# MMCSD register map
Vendor: Texas Instruments
Peripheral module from a debugger description file (folder am437x).
Registers are 32-bit, access per field, no defined reset value unless marked. A register's access mark holds for its fields unless they carry their own. Offsets are as the file gives them; lines under a group give offsets from that group; [hi:lo] are bit positions; {n}, {i} and the like mark numbered series; 'fields as' and 'values as' point back to an identical list; <NAME> marks a mode.

## MMCSD (part 1 of 2)
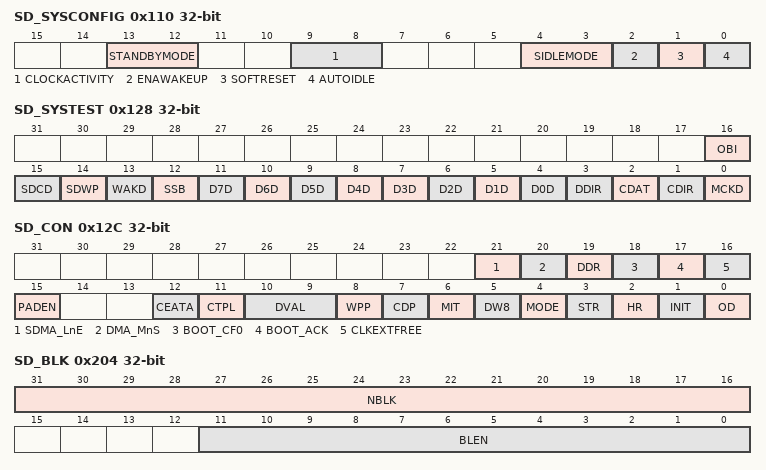
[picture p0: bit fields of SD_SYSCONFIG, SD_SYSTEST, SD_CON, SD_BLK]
0x110 SD_SYSCONFIG — This register allows controlling various parameters of the OCP interface.
  [13:12] STANDBYMODE rw — Master interface power Management, standby/wait control. [[br]]The bit field is only useful when generic parameter MADMA_EN (Master ADMA enable) is set as active, otherwise it is a read only register read a 0.
    3=en_4_0x3 (Smart-Standby wake-up-capable modelocal initiator standby status depends on local conditions, i.e. the module's functional requirement from the initiator. IP module can generate (master-related) wake-up events when in standby state. Mode is only relevant if the appropriate IP module "mwake-up" output is implemented. Functional clock is maintained. Interface clock may be switched off.); 2=en_3_0x2 (Smart-standby modelocal initiator standby status depends on local conditions, i.e. the module's functional requirement from the initiator. IP module shall not generate (initiator-related) wake-up events.); 1=en_2_0x1 (No-standby. Mstandby is never asserted.); 0=en_1_0x0 (Force-standby. Mstandby is forced unconditionally.)
  [9:8] CLOCKACTIVITY rw — Clocks activity during wake up mode period. [[br]]Bit 8 is the Interface clock. [[br]]Bit 9 is the Functional clock.
    3=en_4_0x3 (Interface and Functional clocks are maintained.); 2=en_3_0x2 (Functional clock is maintained. Interface clock may be switched-off.); 1=en_2_0x1 (Interface clock is maintained. Functional clock may be switched-off.); 0=en_1_0x0 (Interface and Functional clock may be switched off.)
  [4:3] SIDLEMODE rw — Power management
    3=en_4_0x3 (Reserved.); 2=en_3_0x2 (If an idle request is detected, the module will switch to wake up mode based on its internal activity, and the wake up capability can be used if the wake up capability is enabled (bit SD_SYSCONFIG[2] ENAWAKEUP bit is set to 1).); 1=en_2_0x1 (If an idle request is detected, the request is ignored and the module keeps on behaving normally.); 0=en_1_0x0 (If an idle request is detected, the MMC/SD/SDIO host controller acknowledges it unconditionally and goes in Inactive mode. Interrupt and DMA requests are unconditionally deasserted.)
  [2] ENAWAKEUP rw — Wake-up feature control
    1=en_2_0x1 (Wake-up capability is enabled.); 0=en_1_0x0 (Wake-up capability is disabled.)
  [1] SOFTRESET rw — Software reset. [[br]]The bit is automatically reset by the hardware. [[br]]During reset, it always returns 0.
    1=en_4_0x1 (The module is reset.); 1=en_3_0x1 (Trigger a module reset.); 0=en_2_0x0 (Normal mode); 0=en_1_0x0 (No effect)
  [0] AUTOIDLE rw — Internal Clock gating strategy
    1=en_2_0x1 (Automatic clock gating strategy is applied, based on the interconnect and MMC interface activity.); 0=en_1_0x0 (Clocks are free-running.)
0x114 SD_SYSSTATUS ro — This register provides status information about the module excluding the interrupt status information.
  [0] RESETDONE — Internal Reset Monitoring. [[br]]Note the debounce clock, the interface clock and the functional clock shall be provided to the MMC/SD/SDIO host controller to allow the internal reset monitoring.
    1=en_2_0x1 (Reset completed); 0=en_1_0x0 (Internal module reset is on-going)
0x124 SD_CSRE rw — This register enables the host controller to detect card status errors of response type R1, R1b for all cards and of R5, R5b and R6 response for cards types SD or SDIO. When a bit SD_CSRE[i] is set to 1, if the corresponding bit at the same position in the response SD_RSP10[I] is set to 1, the host controller indicates a card error (SD_STAT[28] CERR bit) interrupt status to avoid the host driver reading the response register (SD_RSP10). No automatic card error detection for autoCMD12 is implemented; the host system has to check autoCMD12 response register (SD_RSP76) for possible card errors.
  [31:0] CSRE — Card status response error
0x128 SD_SYSTEST — This register is used to control the signals that connect to I/O pins when the module is configured in system test (SYSTEST) mode for boundary connectivity verification. In SYSTEST mode, a write into SD_CMD register will not start a transfer. The buffer behaves as a stack accessible only by the local host (push and pop operations). In this mode, the Transfer Block Size (SD_BLK[10:0] BLEN bits) and the Blocks count for current transfer (SD_BLK[31:16] NBLK bits) are needed to generate a Buffer write ready interrupt (SD_STAT[4] BWR bit) or a Buffer read ready interrupt (SD_STAT[5] BRR bit) and DMA requests if enabled.
  [16] OBI rw — Out-of-band interrupt (OBI) data value.
    1=en_2_0x1 (The out-of-band interrupt pin is driven high.); 0=en_1_0x0 (The out-of-band interrupt pin is driven low.)
  [15] SDCD rw — Card detect input signal (SDCD) data value
    1=en_2_0x1 (The card detect pin is driven high.); 0=en_1_0x0 (The card detect pin is driven low.)
  [14] SDWP rw — Write protect input signal (SDWP) data value
    1=en_2_0x1 (The write protect pin SDWP is driven high.); 0=en_1_0x0 (The write protect pin SDWP is driven low.)
  [13] WAKD rw — Wake request output signal data value.
    1=en_4_0x1 (No action. Returns 1.); 1=en_3_0x1 (The pin SWAKEUP is driven high.); 0=en_2_0x0 (No action. Returns 0.); 0=en_1_0x0 (The pin SWAKEUP is driven low.)
  [12] SSB rw — Set status bit. [[br]]This bit must be cleared prior attempting to clear a status bit of the interrupt status register (SD_STAT).
    1=en_4_0x1 (No action. Returns 1.); 1=en_3_0x1 (Force to 1 all status bits of the interrupt status register (SD_STAT) only if the corresponding bit field in the Interrupt signal enable register (SD_ISE) is set.); 0=en_2_0x0 (No action. Returns 0.); 0=en_1_0x0 (Clear this SSB bit field. Writing 0 does not clear already set status bits.)
  [11] D7D rw — DAT7 input/output signal data value.
    1=en_4_0x1 (If SD_SYSTEST[3] DDIR bit = 1 (input mode direction), returns the value on the DAT7 line (high) If SD_SYSTEST[3] DDIR bit = 0 (output mode direction), returns 1.); 1=en_3_0x1 (If SD_SYSTEST[3] DDIR bit = 0 (output mode direction), the DAT7 line is driven high. If SD_SYSTEST[3] DDIR bit = 1 (input mode direction), no effect.); 0=en_2_0x0 (If SD_SYSTEST[3] DDIR bit = 0 (output mode direction), the DAT7 line is driven low. If SD_SYSTEST[3] DDIR bit = 1 (input mode direction), no effect.); 0=en_1_0x0 (If SD_SYSTEST[3] DDIR bit = 1 (input mode direction), returns the value on the DAT7 line (low). If SD_SYSTEST[3] DDIR bit = 0 (output mode direction), returns 0.)
  [10] D6D rw — DAT6 input/output signal data value.
    1=en_4_0x1 (If SD_SYSTEST[3] DDIR bit = 1 (input mode direction), returns the value on the DAT6 line (high) If SD_SYSTEST[3] DDIR bit = 0 (output mode direction), returns 1.); 1=en_3_0x1 (If SD_SYSTEST[3] DDIR bit = 0 (output mode direction), the DAT6 line is driven high. If SD_SYSTEST[3] DDIR bit = 1 (input mode direction), no effect.); 0=en_2_0x0 (If SD_SYSTEST[3] DDIR bit = 1 (input mode direction), returns the value on the DAT6 line (low). If SD_SYSTEST[3] DDIR bit = 0 (output mode direction), returns 0.); 0=en_1_0x0 (If SD_SYSTEST[3] DDIR bit = 0 (output mode direction), the DAT6 line is driven low. If SD_SYSTEST[3] DDIR bit = 1 (input mode direction), no effect.)
  [9] D5D rw — DAT5 input/output signal data value.
    1=en_4_0x1 (If SD_SYSTEST[3] DDIR bit = 1 (input mode direction), returns the value on the DAT5 line (high) If SD_SYSTEST[3] DDIR bit = 0 (output mode direction), returns 1.); 1=en_3_0x1 (If SD_SYSTEST[3] DDIR bit = 0 (output mode direction), the DAT5 line is driven high. If SD_SYSTEST[3] DDIR bit = 1 (input mode direction), no effect.); 0=en_2_0x0 (If SD_SYSTEST[3] DDIR bit = 0 (output mode direction), the DAT5 line is driven low. If SD_SYSTEST[3] DDIR bit = 1 (input mode direction), no effect.); 0=en_1_0x0 (If SD_SYSTEST[3] DDIR bit = 1 (input mode direction), returns the value on the DAT5 line (low). If SD_SYSTEST[3] DDIR bit = 0 (output mode direction), returns 0.)
  [8] D4D rw — DAT4 input/output signal data value.
    1=en_4_0x1 (If SD_SYSTEST[3] DDIR bit = 1 (input mode direction), returns the value on the DAT4 line (high) If SD_SYSTEST[3] DDIR bit = 0 (output mode direction), returns 1.); 1=en_3_0x1 (If SD_SYSTEST[3] DDIR bit = 0 (output mode direction), the DAT4 line is driven high. If SD_SYSTEST[3] DDIR bit = 1 (input mode direction), no effect.); 0=en_2_0x0 (If SD_SYSTEST[3] DDIR bit = 1 (input mode direction), returns the value on the DAT4 line (low). If SD_SYSTEST[3] DDIR bit = 0 (output mode direction), returns 0.); 0=en_1_0x0 (If SD_SYSTEST[3] DDIR bit = 0 (output mode direction), the DAT4 line is driven low. If SD_SYSTEST[3] DDIR bit = 1 (input mode direction), no effect.)
  [n+4] D{n}D rw (n=0..3) — DAT{n} input/output signal data value.
    1=en_4_0x1 (If SD_SYSTEST[3] DDIR bit = 0 (output mode direction), the DAT{n} line is driven high. If SD_SYSTEST[3] DDIR bit = 1 (input mode direction), no effect.); 1=en_3_0x1 (If SD_SYSTEST[3] DDIR bit = 1 (input mode direction), returns the value on the DAT{n} line (high) If SD_SYSTEST[3] DDIR bit = 0 (output mode direction), returns 1.); 0=en_2_0x0 (If SD_SYSTEST[3] DDIR bit = 1 (input mode direction), returns the value on the DAT{n} line (low). If SD_SYSTEST[3] DDIR bit = 0 (output mode direction), returns 0.); 0=en_1_0x0 (If SD_SYSTEST[3] DDIR bit = 0 (output mode direction), the DAT{n} line is driven low. If SD_SYSTEST[3] DDIR bit = 1 (input mode direction), no effect.)
  [3] DDIR rw — Control of the DAT[[br]][7:0] pins direction.
    1=en_4_0x1 (No action. Returns 1.); 1=en_3_0x1 (The DAT lines are inputs (card to host).); 0=en_2_0x0 (No action. Returns 0.); 0=en_1_0x0 (The DAT lines are outputs (host to card).)
  [2] CDAT rw — CMD input/output signal data value
    1=en_4_0x1 (If SD_SYSTEST[1] CDIR bit = 0 (output mode direction), the CMD line is driven high. If SD_SYSTEST[1] CDIR bit = 1 (input mode direction), no effect.); 1=en_3_0x1 (If SD_SYSTEST[1] CDIR bit = 1 (input mode direction), returns the value on the CMD line (high) If SD_SYSTEST[1] CDIR bit = 0 (output mode direction), returns 1 .); 0=en_2_0x0 (If SD_SYSTEST[1] CDIR bit = 0 (output mode direction), the CMD line is driven low. If SD_SYSTEST[1] CDIR bit = 1 (input mode direction), no effect.); 0=en_1_0x0 (If SD_SYSTEST[1] CDIR bit = 1 (input mode direction), returns the value on the CMD line (low). If SD_SYSTEST[1] CDIR bit = 0 (output mode direction), returns 0 .)
  [1] CDIR rw — Control of the CMD pin direction
    1=en_4_0x1 (The CMD line is an input (card to host) .); 1=en_3_0x1 (No action. Returns 1.); 0=en_2_0x0 (No action. Returns 0.); 0=en_1_0x0 (The CMD line is an output (host to card).)
  [0] MCKD rw — MMC clock output signal data value
    1=en_4_0x1 (No action. Returns 1.); 1=en_3_0x1 (The output clock is driven high.); 0=en_2_0x0 (No action. Returns 0.); 0=en_1_0x0 (The output clock is driven low.)
0x12C SD_CON — This register is used: To select the functional mode for any card. To send an initialization sequence to any card. To send an initialization sequence to any card. To enable the detection on the mmc_dat[1] signal of a card interrupt for SDIO cards only. It also configures the parameters related to the card detect and write protect input signals
  [21] SDMA_LnE rw — Slave DMA Level/Edge Request. [[br]]The waveform of the DMA request can be configured either edge sensitive with early de-assertion on first access to SD_DATA register or late de-assertion, request remains active until last allowed data written into SD_DATA. [[br]]
    1=en_2_0x1 (Slave DMA level sensitive.); 0=en_1_0x0 (Slave DMA edge sensitive.)
  [20] DMA_MnS rw — DMA Master or Slave selection. [[br]]When this bit is set and the controller is configured to use the DMA, Ocp master interface is used to get datas from system using ADMA2 procedure (direct access to the memory). [[br]]This option is only available if generic parameter MADMA_EN is asserted to 1. [[br]]
    1=en_2_0x1 (Not available on this device.); 0=en_1_0x0 (The controller is slave on data transfers with system.)
  [19] DDR rw — Dual Data Rate mode. [[br]]When this register is set, the controller uses both clock edge to emit or receive data. [[br]]Odd bytes are transmitted on falling edges and even bytes are transmitted on rise edges. [[br]]It only applies on Data bytes and CRC, Start, end bits and CRC status are kept full cycle. [[br]]This bit field is only meaningful and active for even clock divider ratio of SD_SYSCTL[CLKD], it is insensitive to SD_HCTL[HSPE] setting. [[br]]Note: DDR mode is not supported on this device. [[br]]Always set this bit to 0.
    1=en_2_0x1 (Data Bytes and CRC are transmitted on both edges.); 0=en_1_0x0 (Standard modeData are transmitted on a single edge.)
  [18] BOOT_CF0 rw — Boot Status Supported. [[br]]This register is set when the CMD line needs to be forced to 0 for a boot sequence. [[br]]CMD line is driven to 0 after writing in SD_CMD. [[br]]The line is released when this bit field is de-asserted and aborts data transfer in case of a pending transaction. [[br]]
    1=en_4_0x1 (CMD line forced to 0 is enabled and will be active after writing into SD_CMD register.); 1=en_3_0x1 (CMD line is released when it was previously forced to 0 by a boot sequence.); 0=en_2_0x0 (CMD line forced to 0 is enabled.); 0=en_1_0x0 (CMD line not forced.)
  [17] BOOT_ACK rw — Book acknowledge received. [[br]]When this bit is set the controller should receive a boot status on DAT0 line after next command issued. [[br]]If no status is received a data timeout will be generated.
    1=en_2_0x1 (A boot status will be received on DAT0 line after issuing a command.); 0=en_1_0x0 (No acknowledge to be received.)
  [16] CLKEXTFREE rw — External clock free running. [[br]]This register is used to maintain card clock out of transfer transaction to enable slave module (for example to generate a synchronous interrupt on mmc_dat[1] ). [[br]]The Clock will be maintain only if SD_SYSCTL[2] CEN bit is set.
    1=en_2_0x1 (External card clock is maintain even out of active transaction period only if SD_SYSCTL[2] CEN bit is set.); 0=en_1_0x0 (External card clock is cut off outside active transaction period.)
  [15] PADEN rw — Control power for MMC lines. [[br]]This register is only useful when MMC PADs contain power saving mechanism to minimize its leakage power. [[br]]It works as a GPIO that directly control the ACTIVE pin of PADs. [[br]]Excepted for mmc_dat[1] , the signal is also combine outside the module with the dedicated power control SD_CON[11] CTPL bit.
    1=en_2_0x1 (ADPIDLE module pin is forced to active state); 0=en_1_0x0 (ADPIDLE module pin is not forced, it is automatically generated by the MMC fsms.)
  [12] CEATA rw — CE-ATA control mode (MMC cards compliant with CE-ATA). [[br]]This bit selects the active level of the out-of-band interrupt coming from MMC cards. [[br]]The usage of the Out-of-Band signal (OBI) is not supported.
    1=en_2_0x1 (CE-ATA mode. Next commands are considered as CE-ATA commands.); 0=en_1_0x0 (Standard MMC/SD/SDIO mode.)
  [11] CTPL rw — Control Power for mmc_dat[1] line (SD cards). [[br]]By default, this bit is cleared to 0 and the host controller automatically disables all the input buffers outside of a transaction to minimize the leakage current. [[br]]SDIO cards. [[br]]When this bit is set to 1, the host controller automatically disables all the input buffers except the buffer of mmc_dat[1] outside of a transaction in order to detect asynchronous card interrupt on mmc_dat[1] line and minimize the leakage current of the buffers.
    1=en_2_0x1 (Disable all the input buffers except the buffer of mmc_dat[1] outside of a transaction.); 0=en_1_0x0 (Disable all the input buffers outside of a transaction.)
  [10:9] DVAL rw — Debounce filter value (all cards). [[br]]This register is used to define a debounce period to filter the card detect input signal (SDCD). [[br]]The usage of the card detect input signal (SDCD) is optional and depends on the system integration and the type of the connector housing that accommodates the card.
    3=en_4_0x3 (8.4 ms debounce period); 2=en_3_0x2 (1 ms debounce period); 1=en_2_0x1 (231 us debounce period); 0=en_1_0x0 (33 us debounce period)
  [8] WPP rw — Write protect polarity (SD and SDIO cards only). [[br]]This bit selects the active level of the write protect input signal (SDWP). [[br]]The usage of the write protect input signal (SDWP) is optional and depends on the system integration and the type of the connector housing that accommodates the card.
    1=en_2_0x1 (Active low level); 0=en_1_0x0 (Active high level)
  [7] CDP rw — Card detect polarity (all cards). [[br]]This bit selects the active level of the write protect input signal (SDWP). [[br]]The usage of the write protect input signal (SDWP) is optional and depends on the system integration and the type of the connector housing that accommodates the card.
    values as WPP
  [6] MIT rw — MMC interrupt command (MMC cards only). [[br]]This bit must be set to 1, when the next write access to the command register (SD_CMD) is for writing a MMC interrupt command (CMD40) requiring the command timeout detection to be disabled for the command response.
    1=en_2_0x1 (Command timeout disabled.); 0=en_1_0x0 (Command timeout enabled.)
  [5] DW8 rw — [[br]]8-bit mode MMC select (MMC cards only). [[br]]For SD/SDIO cards, this bit must be cleared to 0. [[br]]For MMC card, this bit must be set following a valid SWITCH command (CMD6) with the correct value and extend CSD index written in the argument. [[br]]Prior to this command, the MMC card configuration register (CSD and EXT_CSD) must be verified for compliancy with MMC standard specification.
    1=en_2_0x1 (8-bit data width); 0=en_1_0x0 (1-bit or 4-bit data width)
  [4] MODE rw — Mode select (all cards). [[br]]This bit selects the functional mode.
    1=en_2_0x1 (SYSTEST mode. SYSTEST mode. The signal pins are configured as general-purpose input/output and the 1024-byte buffer is configured as a stack memory accessible only by the local host or system DMA. The pins retain their default type (input, output or in-out). SYSTEST mode is operated under the control of the SYSTEST register.); 0=en_1_0x0 (Functional mode. Transfers to the MMC/SD/SDIO cards follow the card protocol. The MMC clock is enabled. MMC/SD transfers are operated under the control of the SD_CMD register.)
  [3] STR rw — Stream command (MMC cards only). [[br]]This bit must be set to 1 only for the stream data transfers (read or write) of the adtc commands. [[br]]Stream read is a class 1 command (CMD11READ_DAT_UNTIL_STOP). [[br]]Stream write is a class 3 command (CMD20WRITE_DAT_UNTIL_STOP).
    1=en_2_0x1 (Stream oriented data transfer); 0=en_1_0x0 (Block oriented data transfer)
  [2] HR rw — Broadcast host response (MMC cards only). [[br]]This register is used to force the host to generate a [[br]]48-bit response for bc command type. [[br]]It can be used to terminate the interrupt mode by generating a CMD40 response by the core. [[br]]In order to have the host response to be generated in open drain mode, the register SD_CON[OD] must be set to 1. [[br]]When SD_CON[12] CEATA bit is set to 1 and SD_ARG cleared to 0, when writing 0000 0000h into SD_CMD register, the host controller performs a 'command completion signal disable' token (i.e., mmc_cmd line held to 0 during 47 cycles followed by a 1).
    1=en_2_0x1 (The host generates a 48-bit response instead of a command or a command completion signal disable token.); 0=en_1_0x0 (The host does not generate a 48-bit response instead of a command.)
  [1] INIT rw — Send initialization stream (all cards). [[br]]When this bit is set to 1, and the card is idle, an initialization sequence is sent to the card. [[br]]An initialization sequence consists of setting the mmc_cmd line to 1 during 80 clock cycles. [[br]]The initialization sequence is mandatory - but it is not required to do it through this bit - this bit makes it easier. [[br]]Clock divider (SD_SYSCTL[[br]][15:6] CLKD bits) should be set to ensure that 80 clock periods are greater than 1ms. [[br]]Note: In this mode, there is no command sent to the card and no response is expected. [[br]]A command complete interrupt will be generated once the initialization sequence is completed. [[br]]SD_STAT[0] CC bit can be polled.
    1=en_2_0x1 (The host sends an initialization sequence); 0=en_1_0x0 (The host does not send an initialization sequence)
  [0] OD rw — Card open drain mode (MMC cards only). [[br]]This bit must be set to 1 for MMC card commands 1, 2, 3 and 40, and if the MMC card bus is operating in open-drain mode during the response phase to the command sent. [[br]]Typically, during card identification mode when the card is either in idle, ready or ident state. [[br]]It is also necessary to set this bit to 1, for a broadcast host response (see Broadcast host response register SD_CON[2] HR bit).
    1=en_2_0x1 (Open drain or broadcast host response); 0=en_1_0x0 (No open drain)
0x130 SD_PWCNT — This register is used to program a mmc counter to delay command transfers after activating the PAD power, this value depends on PAD characteristics and voltage.
  [15:0] PWRCNT rw — Power counter register. [[br]]This register is used to introduce a delay between the PAD ACTIVE pin assertion and the command issued.
    0xFFFF=en_5_0xFFFF (TCF x 65535 delay (card clock period)); 0xFFFE=en_4_0xFFFE (TCF x 65534 delay (card clock period)); 2=en_3_0x2 (TCF x 2 delay (card clock period)); 1=en_2_0x1 (TCF delay (card clock period)); 0=en_1_0x0 (No additional delay added)
0x200 SD_SDMASA ro — This register is used to program a mmc counter to delay command transfers after activating the PAD power. This value depends on PAD characteristics and voltage.
  [31:0] SDMA_SYSADDR — This register contains the system memory address for a SDMA transfer. [[br]]When the Host Controller stops a SDMA transfer, this register shall point to the system address of the next contiguous data position. [[br]]It can be accessed only if no transaction is executing (i.e., after a transaction has stopped). [[br]]Read operations during transfers may return an invalid value. [[br]]The Host Driver shall initialize this register before starting a SDMA transaction. [[br]]After SDMA has stopped, the next system address of the next contiguous data position can be read from this register. [[br]]The SDMA transfer waits at the every boundary specified by the Host SDMA Buffer Boundary in the Block Size register. [[br]]The Host Controller generates DMA Interrupt to request the Host Driver to update this register. [[br]]The Host Driver sets the next system address of the next data position to this register. [[br]]When the most upper byte of this register (003h) is written, the Host Controller restarts the SDMA transfer. [[br]]When restarting SDMA by the Resume command or by setting Continue Request in the Block Gap Control register, the Host Controller shall start at the next contiguous address stored here in the SDMA System Address register. [[br]]ADMA does not use this register.
0x204 SD_BLK — This register shall be used for any card. SD_BLK[BLEN] is the block size register. SD_BLK[NBLK] is the block count register.
  [31:16] NBLK rw — Blocks count for current transfer. [[br]]This register is enabled when Block count Enable (SD_CMD[1] BCE bit) is set to 1 and is valid only for multiple block transfers. [[br]]Setting the block count to 0 results no data blocks being transferred. [[br]]Note: The host controller decrements the block count after each block transfer and stops when the count reaches zero. [[br]]This register can be accessed only if no transaction is executing (i.e., after a transaction has stopped). [[br]]Read operations during transfers may return an invalid value and write operation will be ignored. [[br]]In suspend context, the number of blocks yet to be transferred can be determined by reading this register. [[br]]When restoring transfer context prior to issuing a Resume command, The local host shall restore the previously saved block count.
    0xFFFF=en_4_0xFFFF (65535 blocks); 2=en_3_0x2 (2 blocks); 1=en_2_0x1 (1 block); 0=en_1_0x0 (Stop count)
  [11:0] BLEN rw — Transfer block size. [[br]]This register specifies the block size for block data transfers. [[br]]Read operations during transfers may return an invalid value, and write operations are ignored. [[br]]When a CMD12 command is issued to stop the transfer, a read of the BLEN field after transfer completion (SD_STAT[1] TC bit set to 1) will not return the true byte number of data length while the stop occurs but the value written in this register before transfer is launched.
    0x800=en_8_0x800 (2048 bytes block length); 0x7FF=en_7_0x7FF (2047 bytes block length); 0x200=en_6_0x200 (512 bytes block length); 0x1FF=en_5_0x1FF (511 bytes block length); 3=en_4_0x3 (3 bytes block length); 2=en_3_0x2 (2 bytes block length); 1=en_2_0x1 (1 byte block length); 0=en_1_0x0 (No data transfer)
0x208 SD_ARG rw — This register contains command argument specified as bit 39-8 of Command-Format. These registers must be initialized prior to sending the command itself to the card (write action into the register SD_CMD register). Only exception is for a command index specifying stuff bits in arguments, making a write unnecessary.
  [31:0] ARG — Command argument bits [31:0] .
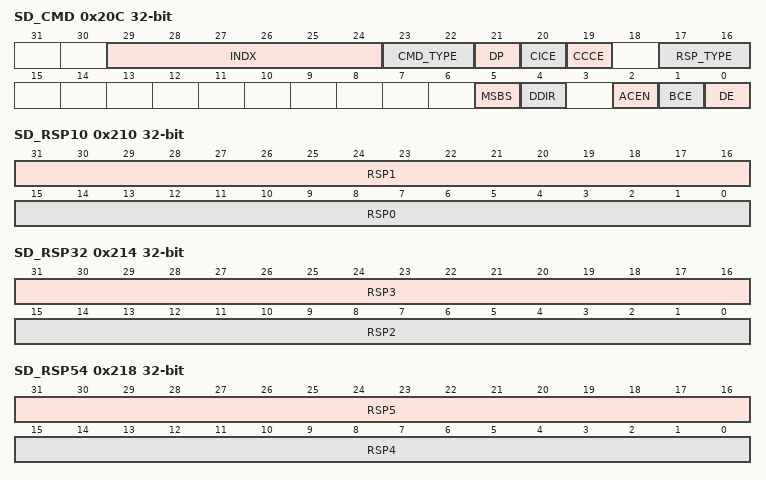
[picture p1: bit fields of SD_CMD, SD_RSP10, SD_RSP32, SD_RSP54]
0x20C SD_CMD — SD_CMD[31:16] = the command register. SD_CMD[15:0] = the transfer mode. This register configures the data and command transfers. A write into the most significant byte send the command. A write into SD_CMD[15:0] registers during data transfer has no effect. This register can be used for any card. In SYSTEST mode, a write into SD_CMD register will not start a transfer.
  [29:24] INDX rw — Command index binary encoded value from 0 to 63 specifying the command number send to card (CMD0 or ACMD0 to CMD63 or ACMD63).
  [23:22] CMD_TYPE rw — Command type. [[br]]This register specifies three types of special commands: Suspend, Resume and Abort. [[br]]These bits shall be cleared to 0b00 for all other commands.
    3=en_4_0x3 (Upon CMD12 or CMD52 "I/O Abort" command); 2=en_3_0x2 (Upon CMD52 "Function Select" operation); 1=en_2_0x1 (Upon CMD52 "Bus Suspend" operation); 0=en_1_0x0 (Others commands)
  [21] DP rw — Data present select. [[br]]This register indicates that data is present and mmc_dat line shall be used. [[br]]It must be cleared to 0 in the following conditions: Command using only mmc_cmd line. [[br]]Command with no data transfer but using busy signal on mmc_dat0. [[br]]Resume command.
    1=en_2_0x1 (Command with data transfer); 0=en_1_0x0 (Command with no data transfer)
  [20] CICE rw — Command Index check enable. [[br]]This bit must be set to 1 to enable index check on command response to compare the index field in the response against the index of the command. [[br]]If the index is not the same in the response as in the command, it is reported as a command index error (SD_STAT[19] CIE bit set to1) Note: The CICE bit cannot be configured for an Auto CMD12, then index check is automatically checked when this command is issued.
    1=en_2_0x1 (Index check enable); 0=en_1_0x0 (Index check disable)
  [19] CCCE rw — Command CRC check enable. [[br]]This bit must be set to 1 to enable CRC7 check on command response to protect the response against transmission errors on the bus. [[br]]If an error is detected, it is reported as a command CRC error (SD_STAT[17] CCRC bit set to 1). [[br]]Note: The CCCE bit cannot be configured for an Auto CMD12, and then CRC check is automatically checked when this command is issued.
    1=en_2_0x1 (CRC7 check enable); 0=en_1_0x0 (CRC7 check disable)
  [17:16] RSP_TYPE rw — Response type. [[br]]This bits defines the response type of the command.
    3=en_4_0x3 (Response Length 48 bits with busy after response); 2=en_3_0x2 (Response Length 48 bits); 1=en_2_0x1 (Response Length 136 bits); 0=en_1_0x0 (No response)
  [5] MSBS rw — Multi/Single block select. [[br]]This bit must be set to 1 for data transfer in case of multi block command. [[br]]For any others command this bit shall be cleared to 0.
    1=en_2_0x1 (Multi block. When Block Count is disabled (SD_CMD[1] BCE bit is cleared to 0) in Multiple block transfers (SD_CMD[5] MSBS bit is set to 1), the module can perform infinite transfer.); 0=en_1_0x0 (Single block. If this bit is 0, it is not necessary to set the register SD_BLK[31:16] NBLK bits.)
  [4] DDIR rw — Data transfer Direction. [[br]]Select This bit defines either data transfer will be a read or a write.
    1=en_2_0x1 (Data Read (card to host)); 0=en_1_0x0 (Data Write (host to card))
  [2] ACEN rw — Auto CMD12 Enable (SD cards only). [[br]]When this bit is set to 1, the host controller issues a CMD12 automatically after the transfer completion of the last block. [[br]]The Host Driver shall not set this bit to issue commands that do not require CMD12 to stop data transfer. [[br]]In particular, secure commands do not require CMD12. [[br]]For CE-ATA commands (SD_CON[12] CEATA bit set to 1), auto CMD12 is useless[[br]] therefore when this bit is set the mechanism to detect command completion signal, named CCS, interrupt is activated.
    1=en_2_0x1 (Auto CMD12 enable or CCS detection enabled.); 0=en_1_0x0 (Auto CMD12 disable)
  [1] BCE rw — Block Count Enable (Multiple block transfers only). [[br]]This bit is used to enable the block count register (SD_BLK[[br]][31:16] NBLK bits). [[br]]When Block Count is disabled (SD_CMD[1] BCE bit is cleared to 0) in Multiple block transfers (SD_CMD[5] MSBS bits is set to 1), the module can perform infinite transfer.
    1=en_2_0x1 (Block count enabled for multiple block transfer with known number of blocks); 0=en_1_0x0 (Block count disabled for infinite transfer.)
  [0] DE rw — DMA Enable. [[br]]This bit is used to enable DMA mode for host data access.
    1=en_2_0x1 (DMA mode enable); 0=en_1_0x0 (DMA mode disable)
0x210 SD_RSP10 ro — This 32-bit register holds bits positions [31:0] of command response type R1, R1b, R2, R3, R4, R5, R5b, or R6.
  [31:16] RSP1 — Command Response [[br]][31:16]
  [15:0] RSP0 — Command Response [[br]][15:0]
0x214 SD_RSP32 ro — This 32-bit register holds bits positions [63:32] of command response type R2.
  [31:16] RSP3 — Command Response [[br]][63:48]
  [15:0] RSP2 — Command Response [[br]][47:32]
0x218 SD_RSP54 ro — This 32-bit register holds bits positions [95:64] of command response type R2.
  [31:16] RSP5 — Command Response [[br]][95:80]
  [15:0] RSP4 — Command Response [[br]][79:64]
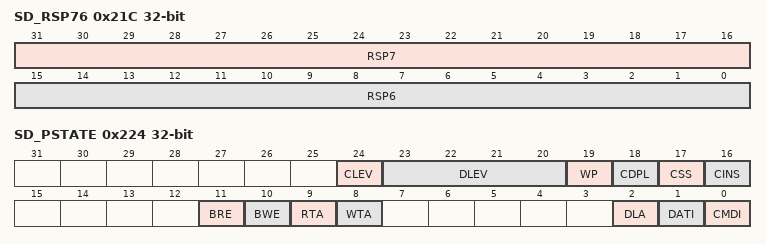
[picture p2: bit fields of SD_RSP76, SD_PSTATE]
0x21C SD_RSP76 ro — This 32-bit register holds bits positions [127:96] of command response type R2.
  [31:16] RSP7 — Command Response [[br]][127:112]
  [15:0] RSP6 — Command Response [[br]][111:96]
0x220 SD_DATA rw — This register is the 32-bit entry point of the buffer for read or write data transfers. The buffer size is 32bitsx256(1024 bytes). Bytes within a word are stored and read in little endian format. This buffer can be used as two 512 byte buffers to transfer data efficiently without reducing the throughput. Sequential and contiguous access is necessary to increment the pointer correctly. Random or skipped access is not allowed. In little endian, if the local host accesses this register byte-wise or 16bit-wise, the least significant byte (bits [7:0]) must always be written/read first. The update of the buffer address is done on the most significant byte write for full 32-bit DATA register or on the most significant byte of the last word of block transfer. Example 1Byte or 16-bit access: Mbyteen[3:0]=0001 (1-byte) => Mbyteen[3:0]=0010 (1-byte) => Mbyteen[3:0]=1100 (2-bytes) OK. Mbyteen[3:0]=0001 (1-byte) => Mbyteen[3:0]=0010 (1-byte) => Mbyteen[3:0]=0100 (1-byte) OK. Mbyteen[3:0]=0001 (1-byte) => Mbyteen[3:0]=0010 (1-byte) => Mbyteen[3:0]=1000 (1-byte) Bad.
  [31:0] DATA — Data register [31:0]. [[br]]In functional mode (SD_CON[4] MODE bit set to the default value 0): A read access to this register is allowed only when the buffer read enable status is set to 1 (SD_PSTATE[11] BRE bit), otherwise a bad access (SD_STAT[29] BADA bit) is signaled. [[br]]A write access to this register is allowed only when the buffer write enable status is set to 1 (SD_PSTATE[10] BWE bit), otherwise a bad access (SD_STAT[29] BADA bit) is signaled and the data is not written.
0x224 SD_PSTATE ro — The Host can get the status of the Host controller from this 32-bit read only register.
  [24] CLEV — mmc_cmd line signal level. [[br]]This status is used to check the mmc_cmd line level to recover from errors, and for debugging. [[br]]The value of this register after reset depends on the mmc_cmd line level at that time.
    1=en_2_0x1 (The mmc_cmd line level is 1.); 0=en_1_0x0 (The mmc_cmd line level is 0.)
  [23:20] DLEV — mmc_dat[[br]][3:0] line signal level mmc_dat3 equal to or greater than bit 23. [[br]]mmc_dat2 equal to or greater than bit 22. [[br]]mmc_dat1 equal to or greater than bit 21. [[br]]mmc_dat0 equal to or greater than bit 20. [[br]]This status is used to check mmc_dat line level to recover from errors, and for debugging. [[br]]This is especially useful in detecting the busy signal level from mmc_dat0 . [[br]]The value of these registers after reset depends on the mmc_dat lines level at that time.
  [19] WP — Write Protect. [[br]]MMC/SD/SDIO1 only. [[br]]SDIO cards only. [[br]]This bit reflects the write protect input pin (SDWP) level. [[br]]The value of this register after reset depends one the protect input pin (SDWP) level at that time. [[br]]
    1=en_2_0x1 (If SD_CON[8] WPP is cleared to 0 (default), the card is not write protected, otherwise the card is write protected.); 0=en_1_0x0 (If SD_CON[8] WPP is cleared to 0 (default), the card is write protected, otherwise the card is not write protected.)
  [18] CDPL — Card Detect Pin Level. [[br]]MMC/SD/SDIO1 only. [[br]]SDIO cards only. [[br]]This bit reflects the inverse value of the card detect input pin (SDCD). [[br]]Debouncing is not performed on this bit and is valid only when Card State is stable. [[br]](SD_PSTATE[17] is set to 1). [[br]]This bit must be debounced by software. [[br]]The value of this register after reset depends on the card detect input pin (SDCD) level at that time. [[br]]
    1=en_2_0x1 (The value of the card detect input pin (SDCD) is 0.); 0=en_1_0x0 (The value of the card detect input pin (SDCD) is 1.)
  [17] CSS — Card State Stable. [[br]]This bit is used for testing. [[br]]It is set to 1 only when Card Detect Pin Level is stable (SD_PSTATE[18] CPDL). [[br]]Debouncing is performed on the card detect input pin (SDCD) to detect card stability. [[br]]This bit is not affected by software reset. [[br]]
    1=en_2_0x1 (Reset or Debouncing.); 0=en_1_0x0 (Reset or Debouncing.)
  [16] CINS — Card inserted. [[br]]This bit is the debounced value of the card detect input pin (SDCD). [[br]]An inactive to active transition of the card detect input pin (SDCD) will generate a card insertion interrupt (SD_STAT[CINS]). [[br]]A active to inactive transition of the card detect input pin (SDCD) will generate a card removal interrupt (SD_STAT[REM]). [[br]]This bit is not affected by a software reset. [[br]]
    1=en_2_0x1 (If SD_CON[CDP] is cleared to 0 (default), the card has been inserted from the card slot. If SD_CON[CDP] is set to 1, no card is detected. The card may have been removed from the card slot.); 0=en_1_0x0 (If SD_CON[CDP] is cleared to 0 (default), no card is detected. The card may have been removed from the card slot. If SD_CON[CDP] is set to 1, the card has been inserted.)
  [11] BRE — Buffer read enable. [[br]]This bit is used for non-DMA read transfers. [[br]]It indicates that a complete block specified by SD_BLK[[br]][10:0] BLEN bits has been written in the buffer and is ready to be read. [[br]]It is cleared to 0 when the entire block is read from the buffer. [[br]]It is set to 1 when a block data is ready in the buffer and generates the Buffer read ready status of interrupt (SD_STAT[5] BRR bit).
    1=en_2_0x1 (Read BLEN bytes enable. Readable data exists in the buffer.); 0=en_1_0x0 (Read BLEN bytes disable)
  [10] BWE — Buffer Write enable. [[br]]This status is used for non-DMA write transfers. [[br]]It indicates if space is available for write data.
    1=en_2_0x1 (There is enough space in the buffer to write BLEN bytes of data.); 0=en_1_0x0 (There is no room left in the buffer to write BLEN bytes of data.)
  [9] RTA — Read transfer active. [[br]]This status is used for detecting completion of a read transfer. [[br]]It is set to 1 after the end bit of read command or by activating a continue request (SD_HCTL[17] CR bit) following a stop at block gap request. [[br]]This bit is cleared to 0 when all data have been read by the local host after last block or after a stop at block gap request.
    1=en_2_0x1 (Read data transfer on going.); 0=en_1_0x0 (No valid data on the mmc_dat lines.)
  [8] WTA — Write transfer active. [[br]]This status indicates a write transfer active. [[br]]It is set to 1 after the end bit of write command or by activating a continue request (SD_HCTL[17] CR bit) following a stop at block gap request. [[br]]This bit is cleared to 0 when CRC status has been received after last block or after a stop at block gap request.
    1=en_2_0x1 (Write data transfer on going.); 0=en_1_0x0 (No valid data on the mmc_dat lines.)
  [2] DLA — mmc_dat line active. [[br]]This status bit indicates whether one of the mmc_dat lines is in use. [[br]]In the case of read transactions (card to host)This bit is set to 1 after the end bit of read command or by activating continue request SD_HCTL[17] CR bit. [[br]]This bit is cleared to 0 when the host controller received the end bit of the last data block or at the beginning of the read wait mode. [[br]]In the case of write transactions (host to card)This bit is set to 1 after the end bit of write command or by activating continue request SD_HCTL[17] CR bit. [[br]]This bit is cleared to 0 on the end of busy event for the last block. [[br]]The host controller must wait 8 clock cycles with line not busy to really consider not "busy state" or after the busy block as a result of a stop at gap request.
    1=en_2_0x1 (mmc_dat line active); 0=en_1_0x0 (mmc_dat line inactive)
  [1] DATI — Command inhibit (mmc_dat). [[br]]This status bit is generated if either mmc_dat line is active (SD_PSTATE[2] DLA bit) or Read transfer is active (SD_PSTATE[9] RTA bit) or when a command with busy is issued. [[br]]This bit prevents the local host to issue a command. [[br]]A change of this bit from 1 to 0 generates a transfer complete interrupt (SD_STAT[1] TC bit).
    1=en_2_0x1 (Issuing of command using mmc_dat lines is not allowed); 0=en_1_0x0 (Issuing of command using the mmc_dat lines is allowed)
  [0] CMDI — Command inhibit(mmc_cmd). [[br]]This status bit indicates that the mmc_cmd line is in use. [[br]]This bit is cleared to 0 when the most significant byte is written into the command register. [[br]]This bit is not set when Auto CMD12 is transmitted. [[br]]This bit is cleared to 0 in either the following cases: After the end bit of the command response, excepted if there is a command conflict error (SD_STAT[17] CCRC bit or SD_STAT[18] CEB bit set to 1) or a Auto CMD12 is not executed (SD_AC12[0] ACNE bit). [[br]]After the end bit of the command without response (SD_CMD[[br]][17:16] RSP_TYPE bits set to "00"). [[br]]In case of a command data error is detected (SD_STAT[19] CTO bit set to 10, this register is not automatically cleared.
    1=en_2_0x1 (Issuing of command using mmc_cmd line is not allowed); 0=en_1_0x0 (Issuing of command using mmc_cmd line is allowed)
